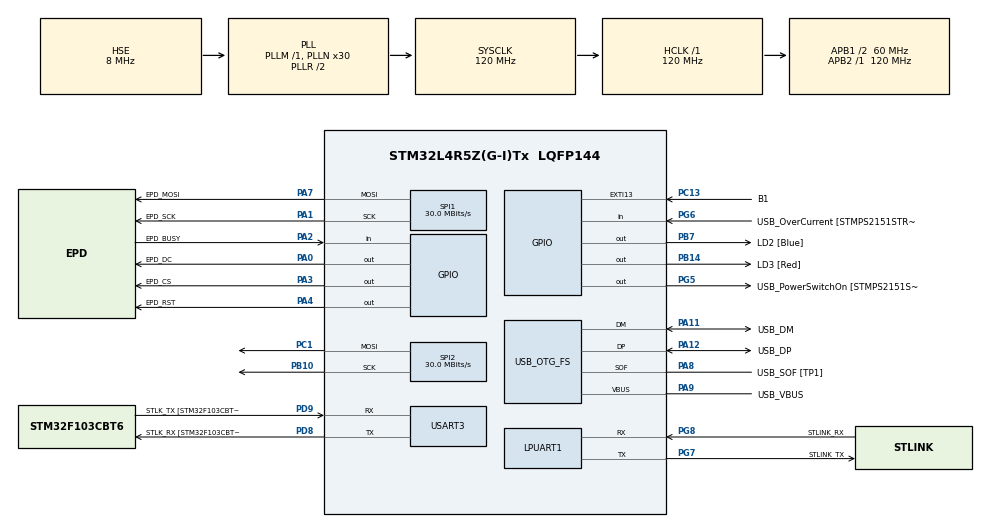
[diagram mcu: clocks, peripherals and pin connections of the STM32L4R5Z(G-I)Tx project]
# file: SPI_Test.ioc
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Dma.Request0=SPI1_TX
Dma.SPI1_TX.0.Direction=DMA_MEMORY_TO_PERIPH
Dma.SPI1_TX.0.EventEnable=DISABLE
Dma.SPI1_TX.0.Instance=DMA1_Channel1
Dma.SPI1_TX.0.MemDataAlignment=DMA_MDATAALIGN_BYTE
Dma.SPI1_TX.0.MemInc=DMA_MINC_ENABLE
Dma.SPI1_TX.0.Mode=DMA_NORMAL
Dma.SPI1_TX.0.PeriphDataAlignment=DMA_PDATAALIGN_BYTE
Dma.SPI1_TX.0.PeriphInc=DMA_PINC_DISABLE
Dma.SPI1_TX.0.Polarity=HAL_DMAMUX_REQUEST_GEN_RISING
Dma.SPI1_TX.0.Priority=DMA_PRIORITY_LOW
Dma.SPI1_TX.0.RequestNumber=1
Dma.SPI1_TX.0.SignalID=NONE
Dma.SPI1_TX.0.SyncEnable=DISABLE
Dma.SPI1_TX.0.SyncPolarity=HAL_DMAMUX_SYNC_NO_EVENT
Dma.SPI1_TX.0.SyncRequestNumber=1
Dma.SPI1_TX.0.SyncSignalID=NONE
Mcu.Family=STM32L4
Mcu.Name=STM32L4R5Z(G-I)Tx
Mcu.Package=LQFP144
NVIC.DMA1_Channel1_IRQn=true\:0\:0\:false\:false\:true\:false\:true
NVIC.PriorityGroup=NVIC_PRIORITYGROUP_4
PA0.GPIO_Label=EPD_DC
PA0.GPIO_Speed=GPIO_SPEED_FREQ_HIGH
PA0.Signal=GPIO_Output
PA1.GPIO_Label=EPD_SCK
PA1.Mode=TX_Only_Simplex_Unidirect_Master
PA1.Signal=SPI1_SCK
PA10.GPIO_Label=USB_ID
PA10.Signal=USB_OTG_FS_ID
PA11.GPIO_Label=USB_DM
PA11.Mode=Device_Only
PA11.Signal=USB_OTG_FS_DM
PA12.GPIO_Label=USB_DP
PA12.Mode=Device_Only
PA12.Signal=USB_OTG_FS_DP
PA13\ (JTMS/SWDIO).GPIO_Label=TMS
PA13\ (JTMS/SWDIO).Mode=Trace_Asynchronous_SW
PA13\ (JTMS/SWDIO).Signal=SYS_JTMS-SWDIO
PA14\ (JTCK/SWCLK).GPIO_Label=TCK
PA14\ (JTCK/SWCLK).Mode=Trace_Asynchronous_SW
PA14\ (JTCK/SWCLK).Signal=SYS_JTCK-SWCLK
PA2.GPIO_Label=EPD_BUSY
PA2.Signal=GPIO_Input
PA3.GPIO_Label=EPD_CS
PA3.GPIO_Speed=GPIO_SPEED_FREQ_HIGH
PA3.Signal=GPIO_Output
PA4.GPIO_Label=EPD_RST
PA4.GPIO_Speed=GPIO_SPEED_FREQ_HIGH
PA4.Signal=GPIO_Output
PA7.GPIO_Label=EPD_MOSI
PA7.Mode=TX_Only_Simplex_Unidirect_Master
PA7.Signal=SPI1_MOSI
PA8.GPIO_Label=USB_SOF [TP1]
PA8.Mode=Activate_SOF_FS
PA8.Signal=USB_OTG_FS_SOF
PA9.GPIO_Label=USB_VBUS
PA9.Mode=Activate_VBUS
PA9.Signal=USB_OTG_FS_VBUS
PB10.Mode=TX_Only_Simplex_Unidirect_Master
PB10.Signal=SPI2_SCK
PB14.GPIO_Label=LD3 [Red]
PB14.Signal=GPIO_Output
PB3\ (JTDO/TRACESWO).GPIO_Label=SWO
PB3\ (JTDO/TRACESWO).Mode=Trace_Asynchronous_SW
PB3\ (JTDO/TRACESWO).Signal=SYS_JTDO-SWO
PB7.GPIO_Label=LD2 [Blue]
PB7.Signal=GPIO_Output
PC1.Mode=TX_Only_Simplex_Unidirect_Master
PC1.Signal=SPI2_MOSI
PC13.GPIO_Label=B1
PC13.Signal=GPXTI13
PC14-OSC32_IN\ (PC14).Mode=LSE-External-Oscillator
PC14-OSC32_IN\ (PC14).Signal=RCC_OSC32_IN
PC15-OSC32_OUT\ (PC15).Mode=LSE-External-Oscillator
PC15-OSC32_OUT\ (PC15).Signal=RCC_OSC32_OUT
PD8.GPIO_Label=STLK_RX [STM32F103CBT6_PA3]
PD8.Mode=Asynchronous
PD8.Signal=USART3_TX
PD9.GPIO_Label=STLK_TX [STM32F103CBT6_PA2]
PD9.Mode=Asynchronous
PD9.Signal=USART3_RX
PG5.GPIO_Label=USB_PowerSwitchOn [STMPS2151STR_EN]
PG5.Signal=GPIO_Output
PG6.GPIO_Label=USB_OverCurrent [STMPS2151STR_FAULT]
PG6.Signal=GPIO_Input
PG7.GPIO_Label=STLINK_TX
PG7.Mode=Asynchronous
PG7.Signal=LPUART1_TX
PG8.GPIO_Label=STLINK_RX
PG8.Mode=Asynchronous
PG8.Signal=LPUART1_RX
PH0-OSC_IN\ (PH0).Mode=HSE-External-Clock-Source
PH0-OSC_IN\ (PH0).Signal=RCC_OSC_IN
PH1-OSC_OUT\ (PH1).Signal=RCC_OSC_OUT
ProjectManager.HeapSize=0x200
ProjectManager.StackSize=0x400
ProjectManager.TargetToolchain=STM32CubeIDE
RCC.48MHZClocksFreq_Value=24000000
RCC.ADCFreq_Value=48000000
RCC.AHBFreq_Value=120000000
RCC.APB1CLKDivider=RCC_HCLK_DIV2
RCC.APB1Freq_Value=60000000
RCC.APB1TimFreq_Value=120000000
RCC.APB2Freq_Value=120000000
RCC.APB2TimFreq_Value=120000000
RCC.CortexFreq_Value=120000000
RCC.HCLKFreq_Value=120000000
RCC.HSE_VALUE=8000000
RCC.HSI48_VALUE=48000000
RCC.HSI_VALUE=16000000
RCC.MSI_VALUE=4000000
RCC.PLLMUL=RCC_PLL_MUL9
RCC.PLLN=30
RCC.PLLSAI1N=12
RCC.PLLSourceVirtual=RCC_PLLSOURCE_HSE
RCC.PRESCALERUSB=RCC_USBCLKSOURCE_PLL_DIV1_5
RCC.SYSCLKFreq_VALUE=120000000
RCC.SYSCLKSource=RCC_SYSCLKSOURCE_PLLCLK
RCC.SYSCLKSourceVirtual=RCC_SYSCLKSOURCE_PLLCLK
RCC.USBFreq_Value=48000000
RCC.VCOOutputFreq_Value=240000000
SPI1.BaudRatePrescaler=SPI_BAUDRATEPRESCALER_4
SPI1.CalculateBaudRate=30.0 MBits/s
SPI1.DataSize=SPI_DATASIZE_8BIT
SPI1.Direction=SPI_DIRECTION_2LINES
SPI1.Mode=SPI_MODE_MASTER
SPI1.VirtualType=VM_MASTER
SPI2.CalculateBaudRate=30.0 MBits/s
SPI2.Direction=SPI_DIRECTION_2LINES
SPI2.Mode=SPI_MODE_MASTER
SPI2.VirtualType=VM_MASTER
USART3.VirtualMode-Asynchronous=VM_ASYNC
USB_OTG_FS.VirtualMode=Device_Only
board=NUCLEO-L4R5ZI

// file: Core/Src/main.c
/* USER CODE BEGIN Header */
/**
  ******************************************************************************
  * @file           : main.c
  * @brief          : Main program body
  ******************************************************************************
  * @attention
  *
  * <h2><center>&copy; Copyright (c) 2019 STMicroelectronics.
  * All rights reserved.</center></h2>
  *
  * This software component is licensed by ST under BSD 3-Clause license,
  * the "License"; You may not use this file except in compliance with the
  * License. You may obtain a copy of the License at:
  *                        opensource.org/licenses/BSD-3-Clause
  *
  ******************************************************************************
  */
/* USER CODE END Header */

#include "main.h"
#include "dma.h"
#include "usart.h"
#include "spi.h"
#include "usb_otg.h"
#include "gpio.h"

void SystemClock_Config(void);

int main(void)
{

  /* MCU Configuration--------------------------------------------------------*/
  /* Reset of all peripherals, Initializes the Flash interface and the Systick. */
  HAL_Init();
  /* Configure the system clock */
  SystemClock_Config();

  /* Initialize all configured peripherals */
  MX_GPIO_Init();
  MX_LPUART1_UART_Init();
  MX_USART3_UART_Init();
  MX_USB_OTG_FS_PCD_Init();
  MX_DMA_Init();
  MX_SPI1_Init();
  MX_SPI2_Init();

  //HAL_GPIO_WritePin(EPD_CS_GPIO_Port, EPD_CS_Pin, GPIO_PIN_SET);
  uint16_t big = 65535;
  uint8_t pic[big];
  uint8_t test = 0xab;
  for(int i = 0; i<big; i++)
  {
	  pic[i]=i;
  }
  uint8_t *add = &pic[0];
  /* Infinite loop */
  /* USER CODE BEGIN WHILE */

  while (1)
  {

	  //HAL_Delay(100);
	  //HAL_GPIO_TogglePin(LD2_GPIO_Port, LD2_Pin);
	 /* HAL_GPIO_WritePin(EPD_CS_GPIO_Port, EPD_CS_Pin, GPIO_PIN_SET);
	  HAL_SPI_Transmit_DMA(&hspi1, add, big);
	  HAL_GPIO_WritePin(EPD_CS_GPIO_Port, EPD_CS_Pin, GPIO_PIN_RESET);
	  HAL_Delay(100);
	  HAL_GPIO_TogglePin(LD3_GPIO_Port, LD3_Pin);*/

	  spi_comand(&hspi1, &test, 1 );
  }
}

void SystemClock_Config(void)
{
  RCC_OscInitTypeDef RCC_OscInitStruct = {0};
  RCC_ClkInitTypeDef RCC_ClkInitStruct = {0};
  RCC_PeriphCLKInitTypeDef PeriphClkInit = {0};

  /** Configure the main internal regulator output voltage
  */
  if (HAL_PWREx_ControlVoltageScaling(PWR_REGULATOR_VOLTAGE_SCALE1_BOOST) != HAL_OK)
  {
    Error_Handler();
  }
  /** Initializes the CPU, AHB and APB busses clocks
  */
  RCC_OscInitStruct.OscillatorType = RCC_OSCILLATORTYPE_HSE;
  RCC_OscInitStruct.HSEState = RCC_HSE_BYPASS;
  RCC_OscInitStruct.PLL.PLLState = RCC_PLL_ON;
  RCC_OscInitStruct.PLL.PLLSource = RCC_PLLSOURCE_HSE;
  RCC_OscInitStruct.PLL.PLLM = 1;
  RCC_OscInitStruct.PLL.PLLN = 30;
  RCC_OscInitStruct.PLL.PLLP = RCC_PLLP_DIV2;
  RCC_OscInitStruct.PLL.PLLQ = RCC_PLLQ_DIV2;
  RCC_OscInitStruct.PLL.PLLR = RCC_PLLR_DIV2;
  if (HAL_RCC_OscConfig(&RCC_OscInitStruct) != HAL_OK)
  {
    Error_Handler();
  }
  /** Initializes the CPU, AHB and APB busses clocks
  */
  RCC_ClkInitStruct.ClockType = RCC_CLOCKTYPE_HCLK|RCC_CLOCKTYPE_SYSCLK
                              |RCC_CLOCKTYPE_PCLK1|RCC_CLOCKTYPE_PCLK2;
  RCC_ClkInitStruct.SYSCLKSource = RCC_SYSCLKSOURCE_PLLCLK;
  RCC_ClkInitStruct.AHBCLKDivider = RCC_SYSCLK_DIV1;
  RCC_ClkInitStruct.APB1CLKDivider = RCC_HCLK_DIV2;
  RCC_ClkInitStruct.APB2CLKDivider = RCC_HCLK_DIV1;

  if (HAL_RCC_ClockConfig(&RCC_ClkInitStruct, FLASH_LATENCY_5) != HAL_OK)
  {
    Error_Handler();
  }
  PeriphClkInit.PeriphClockSelection = RCC_PERIPHCLK_USART3|RCC_PERIPHCLK_LPUART1
                              |RCC_PERIPHCLK_USB;
  PeriphClkInit.Usart3ClockSelection = RCC_USART3CLKSOURCE_PCLK1;
  PeriphClkInit.Lpuart1ClockSelection = RCC_LPUART1CLKSOURCE_PCLK1;
  PeriphClkInit.UsbClockSelection = RCC_USBCLKSOURCE_PLLSAI1;
  PeriphClkInit.PLLSAI1.PLLSAI1Source = RCC_PLLSOURCE_HSE;
  PeriphClkInit.PLLSAI1.PLLSAI1M = 1;
  PeriphClkInit.PLLSAI1.PLLSAI1N = 12;
  PeriphClkInit.PLLSAI1.PLLSAI1P = RCC_PLLP_DIV2;
  PeriphClkInit.PLLSAI1.PLLSAI1Q = RCC_PLLQ_DIV2;
  PeriphClkInit.PLLSAI1.PLLSAI1R = RCC_PLLR_DIV2;
  PeriphClkInit.PLLSAI1.PLLSAI1ClockOut = RCC_PLLSAI1_48M2CLK;
  if (HAL_RCCEx_PeriphCLKConfig(&PeriphClkInit) != HAL_OK)
  {
    Error_Handler();
  }
}

/* USER CODE BEGIN 4 */
void spi_comand(SPI_HandleTypeDef *hspi, uint8_t *pData, uint16_t Size )
{
	HAL_GPIO_WritePin(EPD_CS_GPIO_Port, EPD_CS_Pin, GPIO_PIN_SET);
	HAL_GPIO_WritePin(EPD_DC_GPIO_Port, EPD_DC_Pin, GPIO_PIN_SET);
	HAL_SPI_Transmit(hspi, pData, Size, 0);
	HAL_GPIO_WritePin(EPD_CS_GPIO_Port, EPD_CS_Pin, GPIO_PIN_RESET);
	HAL_GPIO_WritePin(EPD_CS_GPIO_Port, EPD_CS_Pin, GPIO_PIN_RESET);

}
/* USER CODE END 4 */

void Error_Handler(void)
{
}

/************************ (C) COPYRIGHT STMicroelectronics *****END OF FILE****/
